VERSION ""

NS_ :

BS_:

BU_: SENSOR CTRL ACT

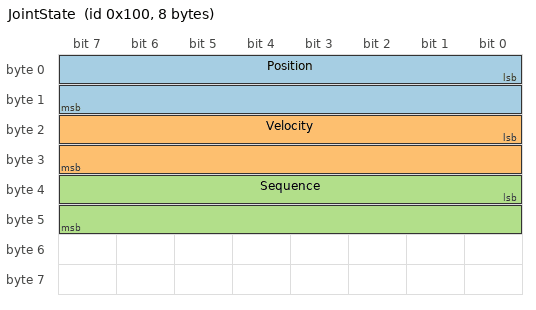
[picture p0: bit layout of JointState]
BO_ 256 JointState: 8 SENSOR
 SG_ Position : 0|16@1+ (0.001,-32.768) [-32.768|32.767] "rad" CTRL,ACT
 SG_ Velocity : 16|16@1+ (0.001,-32.768) [-32.768|32.767] "rad/s" CTRL,ACT
 SG_ Sequence : 32|16@1+ (1,0) [0|65535] "" CTRL,ACT

BO_ 512 JointCommand: 8 CTRL
 SG_ Position : 0|16@1+ (0.001,-32.768) [-32.768|32.767] "rad" ACT
 SG_ Sequence : 32|16@1+ (1,0) [0|65535] "" ACT

BO_ 768 JointFeedback: 8 ACT
 SG_ Position : 0|16@1+ (0.001,-32.768) [-32.768|32.767] "rad" CTRL
 SG_ Sequence : 32|16@1+ (1,0) [0|65535] "" CTRL
